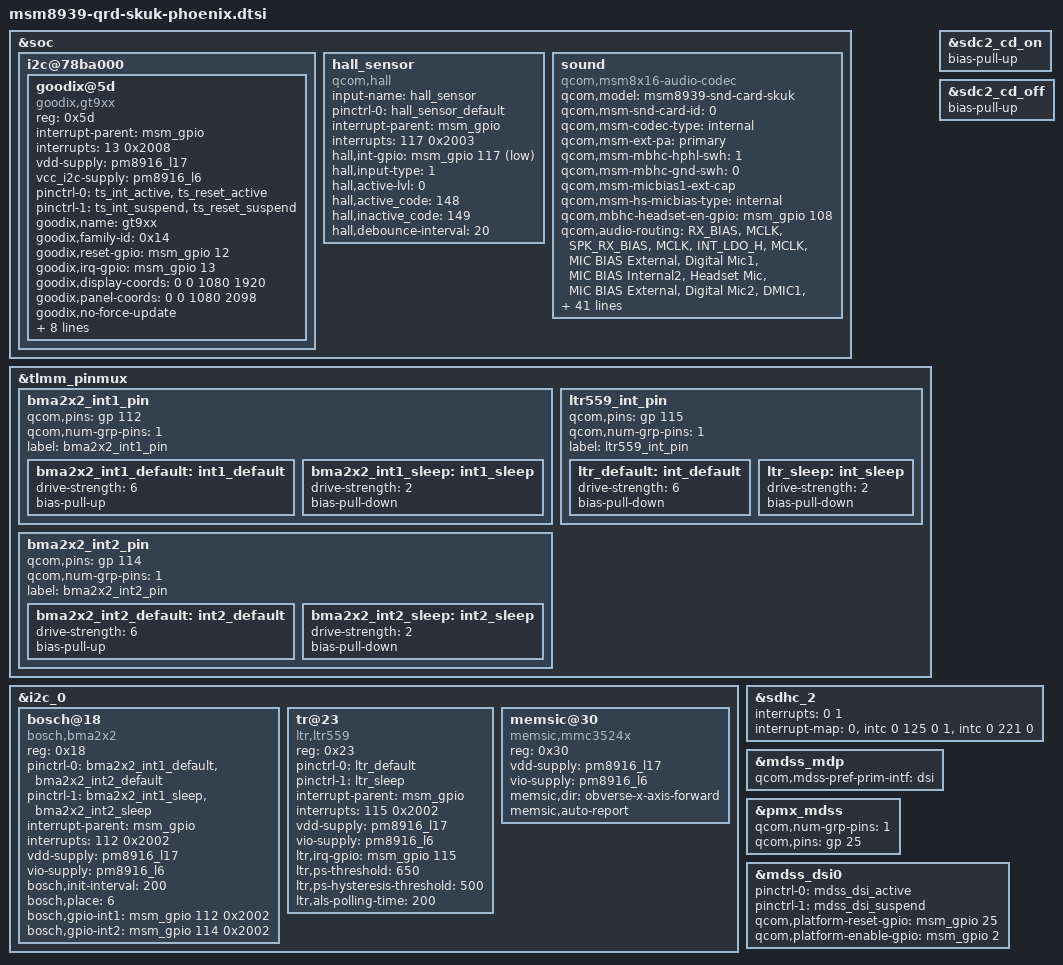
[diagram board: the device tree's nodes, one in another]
/* Copyright (c) 2014-2015, 2020, The Linux Foundation. All rights reserved.
 *
 * This program is free software; you can redistribute it and/or modify
 * it under the terms of the GNU General Public License version 2 and
 * only version 2 as published by the Free Software Foundation.
 *
 * This program is distributed in the hope that it will be useful,
 * but WITHOUT ANY WARRANTY; without even the implied warranty of
 * MERCHANTABILITY or FITNESS FOR A PARTICULAR PURPOSE.  See the
 * GNU General Public License for more details.
 */

#include "msm8939-qrd-phoenix.dtsi"
#include "msm8939-camera-sensor-qrd-phoenix.dtsi"

&soc {
	i2c@78ba000 { /* BLSP1 QUP6 */
		goodix@5d {
			compatible = "goodix,gt9xx";
			reg = <0x5d>;
			interrupt-parent = <&msm_gpio>;
			interrupts = <13 0x2008>;
			vdd-supply = <&pm8916_l17>;
			vcc_i2c-supply = <&pm8916_l6>;
			pinctrl-names = "pmx_ts_active","pmx_ts_suspend";
			pinctrl-0 = <&ts_int_active &ts_reset_active>;
			pinctrl-1 = <&ts_int_suspend &ts_reset_suspend>;
			goodix,name = "gt9xx";
			goodix,family-id = <0x14>;
			goodix,reset-gpio = <&msm_gpio 12 0x0>;
			goodix,irq-gpio = <&msm_gpio 13 0x2008>;
			goodix,display-coords = <0 0 1080 1920>;
			goodix,panel-coords = <0 0 1080 2098>;
			goodix,no-force-update;
			goodix,i2c-pull-up;
			goodix,group-id = <1>;
			goodix,fw-upgrade-id1 = <0x11>;
			goodix,fw-upgrade-id2 = <0x11>;
			goodix,fw-delay-readid-ms = <10>;
			goodix,fw-delay-era-flsh-ms = <2000>;
			goodix,fw-auto-cal;
			goodix,ignore-id-check;
	    };
	};

	hall_sensor {
		compatible = "qcom,hall";
		input-name = "hall_sensor";

		pinctrl-names = "s5712_default";
		pinctrl-0 = <&hall_sensor_default>;
		interrupt-parent = <&msm_gpio>;
		interrupts = <117 0x2003>;
		hall,int-gpio = <&msm_gpio 117 0x2003>;
		hall,input-type = <1>;
		hall,active-lvl = <0>;
		hall,active_code = <148>;
		hall,inactive_code = <149>;
		hall,debounce-interval = <20>;
	};

	sound {
		compatible = "qcom,msm8x16-audio-codec";
		qcom,model = "msm8939-snd-card-skuk";
		qcom,msm-snd-card-id = <0>;
		qcom,msm-codec-type = "internal";
		qcom,msm-ext-pa = "primary";
		qcom,msm-mbhc-hphl-swh = <1>;
		qcom,msm-mbhc-gnd-swh = <0>;
		qcom,msm-micbias1-ext-cap;
		qcom,msm-hs-micbias-type = "internal";
		qcom,mbhc-headset-en-gpio = <&msm_gpio 108 0>;
		qcom,audio-routing =
			"RX_BIAS", "MCLK",
			"SPK_RX_BIAS", "MCLK",
			"INT_LDO_H", "MCLK",
			"MIC BIAS External", "Digital Mic1",
			"MIC BIAS Internal2", "Headset Mic",
			"MIC BIAS External", "Digital Mic2",
			"DMIC1", "MIC BIAS External",
			"AMIC2", "MIC BIAS Internal2",
			"DMIC2", "MIC BIAS External";
		pinctrl-names = "cdc_lines_act",
				"cdc_lines_sus";
		pinctrl-0 = <&cdc_pdm_lines_act &cdc_dmic_lines_act>;
		pinctrl-1 = <&cdc_pdm_lines_sus &cdc_dmic_lines_sus>;
		asoc-platform = <&pcm0>, <&pcm1>, <&voip>, <&voice>,
				<&loopback>, <&compress>, <&hostless>,
				<&afe>, <&lsm>, <&routing>, <&lpa>;
		asoc-platform-names = "msm-pcm-dsp.0", "msm-pcm-dsp.1",
				"msm-voip-dsp", "msm-pcm-voice", "msm-pcm-loopback",
				"msm-compress-dsp", "msm-pcm-hostless", "msm-pcm-afe",
				"msm-lsm-client", "msm-pcm-routing", "msm-pcm-lpa";
		asoc-cpu = <&dai_pri_auxpcm>, <&dai_hdmi>, <&dai_mi2s0>, <&dai_mi2s1>,
				<&dai_mi2s2>, <&dai_mi2s3>, <&sb_0_rx>, <&sb_0_tx>,
				<&sb_1_rx>, <&sb_1_tx>, <&sb_3_rx>, <&sb_3_tx>,
				<&sb_4_rx>, <&sb_4_tx>, <&sb_5_tx>, <&bt_sco_rx>,
				<&bt_sco_tx>, <&bt_a2dp_rx>,
				<&int_fm_rx>, <&int_fm_tx>, <&afe_pcm_rx>,
				<&afe_pcm_tx>, <&afe_proxy_rx>, <&afe_proxy_tx>,
				<&incall_record_rx>, <&incall_record_tx>, <&incall_music_rx>,
				<&incall_music_2_rx>;
		asoc-cpu-names = "msm-dai-q6-auxpcm.1", "msm-dai-q6-hdmi.8", "msm-dai-q6-mi2s.0",
				"msm-dai-q6-mi2s.1", "msm-dai-q6-mi2s.2",
				"msm-dai-q6-mi2s.3", "msm-dai-q6-dev.16384",
				"msm-dai-q6-dev.16385", "msm-dai-q6-dev.16386",
				"msm-dai-q6-dev.16387", "msm-dai-q6-dev.16390",
				"msm-dai-q6-dev.16391", "msm-dai-q6-dev.16392",
				"msm-dai-q6-dev.16393", "msm-dai-q6-dev.16395",
				"msm-dai-q6-dev.12288", "msm-dai-q6-dev.12289",
				"msm-dai-q6-dev.12290", "msm-dai-q6-dev.12292",
				"msm-dai-q6-dev.12293",	"msm-dai-q6-dev.224",
				"msm-dai-q6-dev.225", "msm-dai-q6-dev.241",
				"msm-dai-q6-dev.240", "msm-dai-q6-dev.32771",
				"msm-dai-q6-dev.32772", "msm-dai-q6-dev.32773",
				"msm-dai-q6-dev.32770";
		asoc-codec = <&stub_codec>, <&pm8916_tombak_dig>;
		asoc-codec-names = "msm-stub-codec.1", "tombak_codec";
	};
};


&tlmm_pinmux {
	bma2x2_int1_pin {
		qcom,pins = <&gp 112>;
		qcom,num-grp-pins = <1>;
		label = "bma2x2_int1_pin";
		bma2x2_int1_default: int1_default {
			  drive-strength = <6>;
			  bias-pull-up;
		};
		bma2x2_int1_sleep: int1_sleep {
			  drive-strength = <2>;
			  bias-pull-down;
		};
	};

	bma2x2_int2_pin {
		qcom,pins = <&gp 114>;
		qcom,num-grp-pins = <1>;
		label = "bma2x2_int2_pin";
		bma2x2_int2_default: int2_default {
			  drive-strength = <6>;
			  bias-pull-up;
		};
		bma2x2_int2_sleep: int2_sleep {
			  drive-strength = <2>;
			  bias-pull-down;
		};
	};
	ltr559_int_pin {
		qcom,pins = <&gp 115>;
		qcom,num-grp-pins = <1>;
		label = "ltr559_int_pin";
		ltr_default: int_default {
			  drive-strength = <6>;
			  bias-pull-down;
		};
		ltr_sleep: int_sleep {
			  drive-strength = <2>;
			  bias-pull-down;
		};
	};
};

&i2c_0 { /* BLSP1 QUP2 */
	bosch@18 { /* Accelerometer sensor */
		compatible = "bosch,bma2x2";
		reg = <0x18>;
		pinctrl-names = "bma_default","bma_sleep";
		pinctrl-0 = <&bma2x2_int1_default &bma2x2_int2_default>;
		pinctrl-1 = <&bma2x2_int1_sleep &bma2x2_int2_sleep>;
		interrupt-parent = <&msm_gpio>;
		interrupts = <112 0x2002>;
		vdd-supply = <&pm8916_l17>;
		vio-supply = <&pm8916_l6>;
		bosch,init-interval = <200>;
		bosch,place = <6>;
		bosch,gpio-int1 = <&msm_gpio 112 0x2002>;
		bosch,gpio-int2 = <&msm_gpio 114 0x2002>;
	};

	tr@23 { /* Ambient light and proximity sensor */ 
                        compatible = "ltr,ltr559"; 
                        reg = <0x23>; 
                        pinctrl-names = "default","sleep"; 
                        pinctrl-0 = <&ltr_default>; 
                        pinctrl-1 = <&ltr_sleep>; 
                        interrupt-parent = <&msm_gpio>; 
                        interrupts = <115 0x2002>; 
                        vdd-supply = <&pm8916_l17>; 
                        vio-supply = <&pm8916_l6>; 
                        ltr,irq-gpio = <&msm_gpio 115 0x2002>; 
                        ltr,ps-threshold = <650>; 
                        ltr,ps-hysteresis-threshold = <500>; 
                        ltr,als-polling-time = <200>; 
        }; 

	memsic@30 { /* Magnetic field sensor */
		compatible = "memsic,mmc3524x";
		reg = <0x30>;
		vdd-supply = <&pm8916_l17>;
		vio-supply = <&pm8916_l6>;
		memsic,dir = "obverse-x-axis-forward";
		memsic,auto-report;
	};
};

&sdc2_cd_on {
	bias-pull-up;
};

&sdc2_cd_off {
	bias-pull-up;
};

&sdhc_2 {
	interrupts = <0 1>;
	interrupt-map = <0 &intc 0 125 0
		1 &intc 0 221 0>;
	interrupt-names = "hc_irq", "pwr_irq";
};

&mdss_mdp {
	qcom,mdss-pref-prim-intf = "dsi";
};

&pmx_mdss {
	qcom,num-grp-pins = <1>;
	qcom,pins = <&gp 25>;
};

&mdss_dsi0 {
	pinctrl-names = "mdss_default", "mdss_sleep";
	pinctrl-0 = <&mdss_dsi_active>;
	pinctrl-1 = <&mdss_dsi_suspend>;

	qcom,platform-reset-gpio = <&msm_gpio 25 0>;
	qcom,platform-enable-gpio = <&msm_gpio 2 0>;
};

